# timer register map
Vendor: Texas Instruments
Peripheral module from a debugger description file (folder cc32).
Registers are 32-bit, read-write, no defined reset value unless marked. A register's access mark holds for its fields unless they carry their own. Offsets are as the file gives them; lines under a group give offsets from that group; [hi:lo] are bit positions; {n}, {i} and the like mark numbered series; 'fields as' and 'values as' point back to an identical list; <NAME> marks a mode.

## timer
0x00 CFG — GPTM Configuration
  [2:0] CFG
0x04 TAMR — GPTM Timer A Mode
  [1:0] TAMR
0x08 TBMR — GPTM Timer B Mode
  [1:0] TBMR
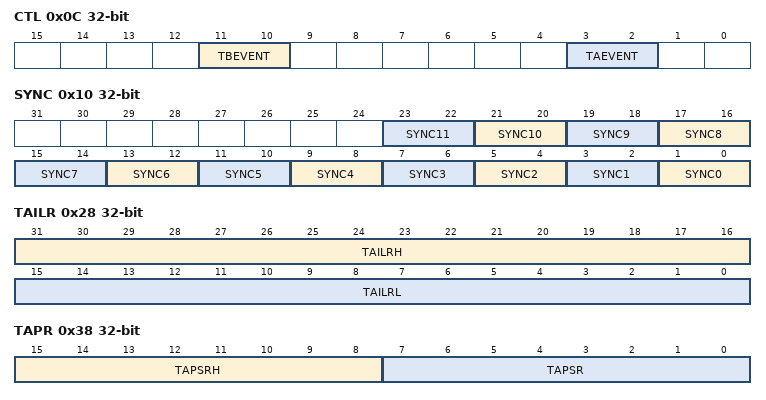
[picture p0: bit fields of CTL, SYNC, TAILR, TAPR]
0x0C CTL — GPTM Control ##### GARNET BEGIN #####
  [11:10] TBEVENT — GPTM Timer B Event Mode
  [3:2] TAEVENT — GPTM Timer A Event Mode
0x10 SYNC — GPTM Synchronize ##### GARNET END #####
  [2n+1:2n] SYNC{n} (n=0..11) — Synchronize GPTM Timer {n}
0x18 IMR access not given — GPTM Interrupt Mask
0x1C RIS access not given — GPTM Raw Interrupt Status
0x20 MIS access not given — GPTM Masked Interrupt Status
0x24 ICR access not given — GPTM Interrupt Clear
0x28 TAILR — GPTM Timer A Interval Load
  [31:16] TAILRH — GPTM Timer A Interval Load Register High
  [15:0] TAILRL — GPTM Timer A Interval Load Register Low
0x2C TBILR — GPTM Timer B Interval Load
  [15:0] TBILRL — GPTM Timer B Interval Load Register
0x30 TAMATCHR access not given — GPTM Timer A Match
0x34 TBMATCHR access not given — GPTM Timer B Match
0x38 TAPR — GPTM Timer A Prescale
  [15:8] TAPSRH — GPTM Timer A Prescale High Byte ##### GARNET END #####
  [7:0] TAPSR — GPTM Timer A Prescale ##### GARNET BEGIN #####
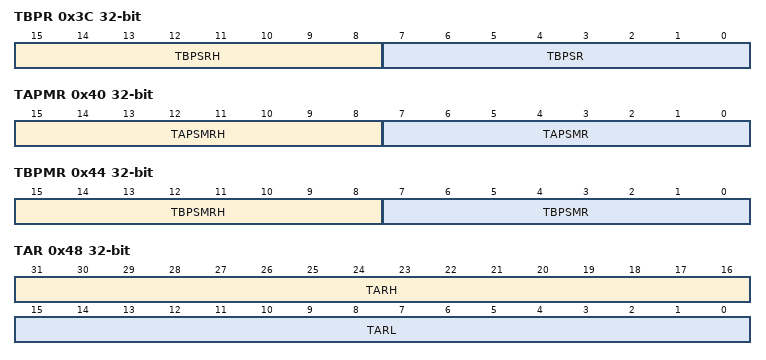
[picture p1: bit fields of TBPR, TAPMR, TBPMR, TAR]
0x3C TBPR — GPTM Timer B Prescale
  [15:8] TBPSRH — GPTM Timer B Prescale High Byte ##### GARNET END #####
  [7:0] TBPSR — GPTM Timer B Prescale ##### GARNET BEGIN #####
0x40 TAPMR — GPTM TimerA Prescale Match
  [15:8] TAPSMRH — GPTM Timer A Prescale Match High Byte ##### GARNET END #####
  [7:0] TAPSMR — GPTM TimerA Prescale Match ##### GARNET BEGIN #####
0x44 TBPMR — GPTM TimerB Prescale Match
  [15:8] TBPSMRH — GPTM Timer B Prescale Match High Byte ##### GARNET END #####
  [7:0] TBPSMR — GPTM TimerB Prescale Match ##### GARNET BEGIN #####
0x48 TAR — GPTM Timer A
  [31:16] TARH — GPTM Timer A Register High
  [15:0] TARL — GPTM Timer A Register Low
0x4C TBR — GPTM Timer B
  [23:0] TBRL
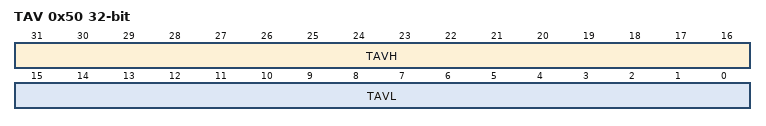
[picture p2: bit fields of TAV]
0x50 TAV — GPTM Timer A Value
  [31:16] TAVH — GPTM Timer A Value High
  [15:0] TAVL — GPTM Timer A Register Low
0x54 TBV — GPTM Timer B Value
  [15:0] TBVL — GPTM Timer B Register
0x58 RTCPD — GPTM RTC Predivide
  [15:0] RTCPD — RTC Predivide Counter Value
0x5C TAPS — GPTM Timer A Prescale Snapshot
  [15:0] PSS — GPTM Timer A Prescaler Snapshot
0x60 TBPS — GPTM Timer B Prescale Snapshot
  [15:0] PSS — GPTM Timer A Prescaler Value
0x64 TAPV — GPTM Timer A Prescale Value
  [15:0] PSV — GPTM Timer A Prescaler Value
0x68 TBPV — GPTM Timer B Prescale Value
  [15:0] PSV — GPTM Timer B Prescaler Value
0x6C DMAEV access not given — GPTM DMA Event
0xFC0 PP — GPTM Peripheral Properties ***************************************************************************
  [3:0] SIZE — Count Size
